# hpb_reva_me10 register map
Registers are access not given, no defined reset value unless marked. A register's access mark holds for its fields unless they carry their own. Offsets are from the block's base; lines under a group give offsets from that group; [hi:lo] are bit positions; {n}, {i} and the like mark numbered series; 'fields as' and 'values as' point back to an identical list; <NAME> marks a mode.

## Memory map
0x40039000 HPB size 0x1000 — HyperBus Memory Controller

## Interrupts
61 HPB — HPB interrupt.

## HPB — HyperBus Memory Controller
Base 0x40039000
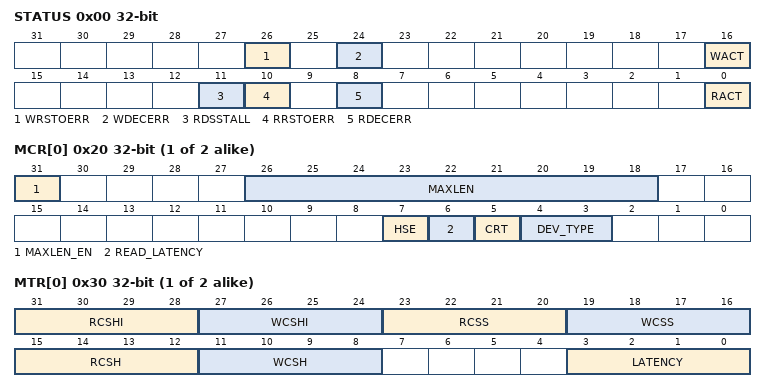
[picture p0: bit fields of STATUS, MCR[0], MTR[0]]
0x00 STATUS — HPB Status Register.
  [26] WRSTOERR — Reset during write error.
    0=No error; 1=err (Error.)
  [24] WDECERR — Write address error.
    0=No error; 1=err (Error.)
  [16] WACT — Write transaction in progress.
    0=No write transaction in progress; 1=Write transaction in progress
  [11] RDSSTALL — Read data stall.
    0=normalop (Read operation normal.); 1=stalled (Read stalled.)
  [10] RRSTOERR — Reset during read error.
    0=No error; 1=err (Error.)
  [8] RDECERR — Read address error.
    0=No error; 1=err (Error.)
  [0] RACT — Read transaction in progress.
    0=No read transaction in progress; 1=Read transaction in progress
0x04 INTEN — HPB Interrupt Enable.
  [1] ERRINTE — Error interrupt enable.
    0=dis (Disable error interrupt.); 1=en (Enable error interrupt.)
0x08 INTFL — HPB Interrupt Status Flags.
  [1] ERRINT — Error interrupt status flags.
    0=No interrupt pending; 1=pending (Error interrupt pending.)
{0x10+4i} MBR[{i}] (i=0..1) — HPB Memory Base Address.
  [31:24] ADDR — Memory Base Address.
{0x20+4i} MCR[{i}] (i=0..1) — HPB Memory Configuration Register.
  [31] MAXLEN_EN — Maximum CS# length enable.
    0=dis (Configurable CS# low time disabled.); 1=en (Configurable CS# low time enabled.)
  [26:18] MAXLEN — Maximum read/write..
  [7] HSE — Xccela half sleep exit.
    0=dis (Half-Sleep exit disabled.); 1=en (Half-Sleep exit enabled.)
  [6] READ_LATENCY — Xccela fixed read latency enable.
    0=Variable read latency; 1=Fixed read latency
  [5] CRT — Configuration register target select.
    0=mem_space (Access memory space.); 1=config_reg_space (Access configuration register space.)
  [4:3] DEV_TYPE — Memory device type select.
    0=hyperFlash; 1=xccelaPSRAM; 2=hyperRAM
{0x30+4i} MTR[{i}] (i=0..1) — HPB Memory Timing Register.
  [31:28] RCSHI — Read chip select high between operations.
  [27:24] WCSHI — Write chip select high between operations.
  [23:20] RCSS — Read chip select setup time to next CK rising edge.
  [19:16] WCSS — Write chip select setup time to next CK rising edge.
  [15:12] RCSH — Read chip select hold after CK falling edge.
  [11:8] WCSH — Write chip select hold after CK falling edge.
  [3:0] LATENCY — RAM Latency Clock Cycles.
    0=5CLK (5 clock cycles.); 1=6CLK (6 clock cycles.); 14=3CLK (3 clock cycles.); 15=4CLK (4 clock cycles.)
